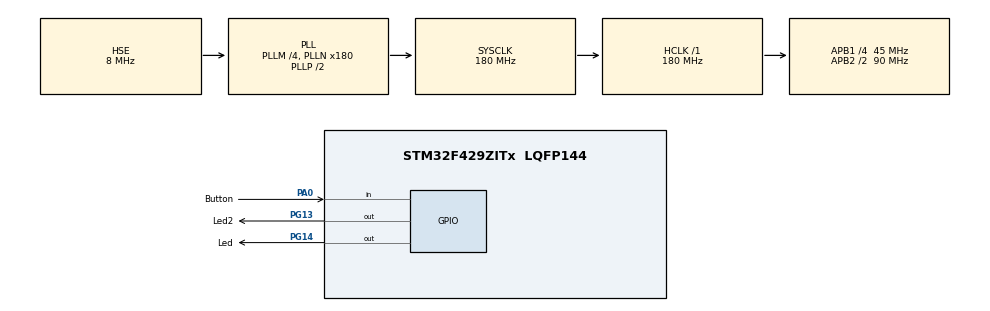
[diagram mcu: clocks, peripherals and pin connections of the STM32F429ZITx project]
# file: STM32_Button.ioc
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Mcu.Family=STM32F4
Mcu.Name=STM32F429ZITx
Mcu.Package=LQFP144
NVIC.PriorityGroup=NVIC_PRIORITYGROUP_4
PA0/WKUP.GPIO_Label=Button
PA0/WKUP.Signal=GPIO_Input
PA13.Mode=Serial_Wire
PA13.Signal=SYS_JTMS-SWDIO
PA14.Mode=Serial_Wire
PA14.Signal=SYS_JTCK-SWCLK
PG13.GPIO_Label=Led2
PG13.Signal=GPIO_Output
PG14.GPIO_Label=Led
PG14.Signal=GPIO_Output
PH0/OSC_IN.Mode=HSE-External-Oscillator
PH0/OSC_IN.Signal=RCC_OSC_IN
PH1/OSC_OUT.Mode=HSE-External-Oscillator
PH1/OSC_OUT.Signal=RCC_OSC_OUT
ProjectManager.HeapSize=0x200
ProjectManager.StackSize=0x400
ProjectManager.TargetToolchain=SW4STM32
RCC.48MHZClocksFreq_Value=90000000
RCC.AHBFreq_Value=180000000
RCC.APB1CLKDivider=RCC_HCLK_DIV4
RCC.APB1Freq_Value=45000000
RCC.APB1TimFreq_Value=90000000
RCC.APB2CLKDivider=RCC_HCLK_DIV2
RCC.APB2Freq_Value=90000000
RCC.APB2TimFreq_Value=180000000
RCC.CortexFreq_Value=180000000
RCC.HCLKFreq_Value=180000000
RCC.HSE_VALUE=8000000
RCC.HSI_VALUE=16000000
RCC.LSE_VALUE=32768
RCC.PLLM=4
RCC.PLLN=180
RCC.PLLSourceVirtual=RCC_PLLSOURCE_HSE
RCC.SYSCLKFreq_VALUE=180000000
RCC.SYSCLKSource=RCC_SYSCLKSOURCE_PLLCLK
RCC.VCOOutputFreq_Value=360000000
board=custom

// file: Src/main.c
/**
  ******************************************************************************
  * @file           : main.c
  * @brief          : Main program body
  ******************************************************************************
  ** This notice applies to any and all portions of this file
  * that are not between comment pairs USER CODE BEGIN and
  * USER CODE END. Other portions of this file, whether
  * inserted by the user or by software development tools
  * are owned by their respective copyright owners.
  *
  * COPYRIGHT(c) 2018 STMicroelectronics
  *
  * Redistribution and use in source and binary forms, with or without modification,
  * are permitted provided that the following conditions are met:
  *   1. Redistributions of source code must retain the above copyright notice,
  *      this list of conditions and the following disclaimer.
  *   2. Redistributions in binary form must reproduce the above copyright notice,
  *      this list of conditions and the following disclaimer in the documentation
  *      and/or other materials provided with the distribution.
  *   3. Neither the name of STMicroelectronics nor the names of its contributors
  *      may be used to endorse or promote products derived from this software
  *      without specific prior written permission.
  *
  * THIS SOFTWARE IS PROVIDED BY THE COPYRIGHT HOLDERS AND CONTRIBUTORS "AS IS"
  * AND ANY EXPRESS OR IMPLIED WARRANTIES, INCLUDING, BUT NOT LIMITED TO, THE
  * IMPLIED WARRANTIES OF MERCHANTABILITY AND FITNESS FOR A PARTICULAR PURPOSE ARE
  * DISCLAIMED. IN NO EVENT SHALL THE COPYRIGHT HOLDER OR CONTRIBUTORS BE LIABLE
  * FOR ANY DIRECT, INDIRECT, INCIDENTAL, SPECIAL, EXEMPLARY, OR CONSEQUENTIAL
  * DAMAGES (INCLUDING, BUT NOT LIMITED TO, PROCUREMENT OF SUBSTITUTE GOODS OR
  * SERVICES; LOSS OF USE, DATA, OR PROFITS; OR BUSINESS INTERRUPTION) HOWEVER
  * CAUSED AND ON ANY THEORY OF LIABILITY, WHETHER IN CONTRACT, STRICT LIABILITY,
  * OR TORT (INCLUDING NEGLIGENCE OR OTHERWISE) ARISING IN ANY WAY OUT OF THE USE
  * OF THIS SOFTWARE, EVEN IF ADVISED OF THE POSSIBILITY OF SUCH DAMAGE.
  *
  ******************************************************************************
  */
#include "main.h"
#include "stm32f4xx_hal.h"

/* USER CODE BEGIN PV */
/* Private variables ---------------------------------------------------------*/

/* USER CODE END PV */

void SystemClock_Config(void);
static void MX_GPIO_Init(void);

/* USER CODE BEGIN PFP */
/* Private function prototypes -----------------------------------------------*/

/* USER CODE END PFP */

/* USER CODE BEGIN 0 */
#define DEBOUNCING_PERIOD 5
#define BLINKING_TIMER 500

typedef enum ButtonState ButtonState;
enum ButtonState{
	BUTTON_RELEASED,
	BUTTON_PRESSED,
	BUTTON_RELEASED_DEBOUNCING,
	BUTTON_PRESSED_DEBOUNCING,
};

typedef struct Button Button;
struct Button{
	ButtonState buttonState;//to keep the state of the button
	int prevTick;
	ButtonState state;//state machine for function handleButton
};

typedef enum LedState LedState;
enum LedState{
	LED_OFF,
	LED_ON,
};

typedef struct LedButtonInfo LedButtonInfo;
struct LedButtonInfo
{
  LedState currentLedState;
  ButtonState previousButtonState;
};

typedef struct LedInfo LedInfo;//for led blink
struct LedInfo
{
	LedState ledState;
	uint32_t prevTick;
};

void varButtoninit(Button *button);
void varStateinit(LedButtonInfo *state);
ButtonState getButtonState(Button *button);
void turnLed(LedState ledState);
void handleButton(Button *button);
void doTapTurnOnTapTurnOffLed(LedButtonInfo *state,Button *Button);
void doBlinking(LedInfo *ledState);
void turnLed2(LedState ledState);

ButtonState getButtonState(Button *button)
{
	return button->buttonState;
}

void turnLed(LedState ledState)
{
	if(ledState == LED_OFF)
	{
		HAL_GPIO_WritePin(Led_GPIO_Port, Led_Pin, GPIO_PIN_RESET);
	}
	else if(ledState == LED_ON)
	{
		HAL_GPIO_WritePin(Led_GPIO_Port, Led_Pin, GPIO_PIN_SET);
	}
}

void turnLed2(LedState ledState)
{
	if(ledState == LED_OFF)
	{
		HAL_GPIO_WritePin(Led2_GPIO_Port, Led2_Pin, GPIO_PIN_RESET);
	}
	else if(ledState == LED_ON)
	{
		HAL_GPIO_WritePin(Led2_GPIO_Port, Led2_Pin, GPIO_PIN_SET);
	}
}

void handleButton(Button *button)
{
	switch(button->state){
		case BUTTON_RELEASED :
			button->buttonState = BUTTON_RELEASED;
			if(HAL_GPIO_ReadPin(Button_GPIO_Port, Button_Pin))
			{
				button->state = BUTTON_PRESSED_DEBOUNCING;
				button->prevTick = HAL_GetTick();
			}
			break;

		case BUTTON_PRESSED_DEBOUNCING :
			if(HAL_GetTick() >= button->prevTick+DEBOUNCING_PERIOD)
			{
				if(HAL_GPIO_ReadPin(Button_GPIO_Port, Button_Pin))
				{
					button->state = BUTTON_PRESSED;
					button->buttonState = BUTTON_PRESSED;
				}
				else
				{
					button->state = BUTTON_RELEASED;
					button->buttonState = BUTTON_RELEASED;
				}
			}
			break;

		case BUTTON_PRESSED :
			button->buttonState = BUTTON_PRESSED;
			if(!HAL_GPIO_ReadPin(Button_GPIO_Port, Button_Pin))
			{
				button->state = BUTTON_RELEASED_DEBOUNCING;
				button->prevTick = HAL_GetTick();
			}
			break;

		case BUTTON_RELEASED_DEBOUNCING :
			if(HAL_GetTick() >= button->prevTick+DEBOUNCING_PERIOD)
			{
				if(!HAL_GPIO_ReadPin(Button_GPIO_Port, Button_Pin))
				{
					button->state = BUTTON_RELEASED;
					button->buttonState = BUTTON_RELEASED;
				}
				else
				{
					button->state = BUTTON_PRESSED;
					button->buttonState = BUTTON_PRESSED;
				}
			}
			break;
	}
}

void doTapTurnOnTapTurnOffLed(LedButtonInfo *state,Button *Button)
{
  int button = state->previousButtonState;
  if(state->currentLedState == LED_OFF)
  {
    switch(button)
    {
      case BUTTON_RELEASED:
        if(getButtonState(Button) == BUTTON_RELEASED)
        {
          state->currentLedState = LED_OFF;
          state->previousButtonState = BUTTON_RELEASED;
        }
        else
        {
          turnLed(LED_ON);
          state->currentLedState = LED_OFF;
          state->previousButtonState = BUTTON_PRESSED;
        }
        break;

      case BUTTON_PRESSED:
        if(getButtonState(Button) == BUTTON_RELEASED)
        {
          state->currentLedState = LED_ON;
          state->previousButtonState = BUTTON_RELEASED;
        }
        else
        {
          state->currentLedState = LED_OFF;
          state->previousButtonState = BUTTON_PRESSED;
        }
        break;

    }
  }

  else if(state->currentLedState == LED_ON)
  {
    switch(button)
    {
      case BUTTON_RELEASED:
        if(getButtonState(Button) == BUTTON_RELEASED)
        {
          state->currentLedState = LED_ON;
          state->previousButtonState = BUTTON_RELEASED;
        }
        else
        {
          state->currentLedState = LED_ON;
          state->previousButtonState = BUTTON_PRESSED;
        }
        break;

      case BUTTON_PRESSED:
        if(getButtonState(Button) == BUTTON_RELEASED)
        {
          turnLed(LED_OFF);
          state->currentLedState = LED_OFF;
          state->previousButtonState = BUTTON_RELEASED;
        }
        else
        {
          state->currentLedState = LED_ON;
          state->previousButtonState = BUTTON_PRESSED;
        }
        break;

    }
  }
}

void varButtoninit(Button *button)
{
  button->state = HAL_GPIO_ReadPin(Button_GPIO_Port, Button_Pin);
  button->buttonState = HAL_GPIO_ReadPin(Button_GPIO_Port, Button_Pin);
  button->prevTick = 0;
}

void varStateinit(LedButtonInfo *state)
{
	state->currentLedState = LED_OFF;
	state->previousButtonState = HAL_GPIO_ReadPin(Button_GPIO_Port, Button_Pin);
}

void ledInfo_Init(LedInfo *ledInfo)
{
	ledInfo->ledState = LED_OFF;
	ledInfo->prevTick = HAL_GetTick();
}

void doBlinking(LedInfo *ledState)
{

	switch(ledState->ledState)
	{
		case LED_OFF :
			if(HAL_GetTick() > ledState->prevTick + BLINKING_TIMER)
			{
				ledState->prevTick = HAL_GetTick();
				ledState->ledState = LED_ON;
				turnLed2(LED_ON);
			}
			break;

		case LED_ON :
			if(HAL_GetTick() > ledState->prevTick + BLINKING_TIMER)
			{
				ledState->prevTick = HAL_GetTick();
				ledState->ledState = LED_OFF;
				turnLed2(LED_OFF);
			}
			break;
	}

}
/* USER CODE END 0 */

int main(void)
{
  /* USER CODE BEGIN 1 */
	  LedButtonInfo state;
	  Button buttonInfo;
	  LedInfo ledState;

	  varButtoninit(&buttonInfo);
	  varStateinit(&state);
	  ledInfo_Init(&ledState);
  /* USER CODE END 1 */

  /* MCU Configuration----------------------------------------------------------*/

  /* Reset of all peripherals, Initializes the Flash interface and the Systick. */
  HAL_Init();

  /* Configure the system clock */
  SystemClock_Config();

  /* Initialize all configured peripherals */
  MX_GPIO_Init();

  /* Infinite loop */
  /* USER CODE BEGIN WHILE */
  while (1)
  {
	  doTapTurnOnTapTurnOffLed(&state,&buttonInfo);
	  handleButton(&buttonInfo);
	  doBlinking(&ledState);
  /* USER CODE END WHILE */

  }

}

void SystemClock_Config(void)
{

  RCC_OscInitTypeDef RCC_OscInitStruct;
  RCC_ClkInitTypeDef RCC_ClkInitStruct;

    /**Configure the main internal regulator output voltage
    */
  __HAL_RCC_PWR_CLK_ENABLE();

  __HAL_PWR_VOLTAGESCALING_CONFIG(PWR_REGULATOR_VOLTAGE_SCALE1);

    /**Initializes the CPU, AHB and APB busses clocks
    */
  RCC_OscInitStruct.OscillatorType = RCC_OSCILLATORTYPE_HSE;
  RCC_OscInitStruct.HSEState = RCC_HSE_ON;
  RCC_OscInitStruct.PLL.PLLState = RCC_PLL_ON;
  RCC_OscInitStruct.PLL.PLLSource = RCC_PLLSOURCE_HSE;
  RCC_OscInitStruct.PLL.PLLM = 4;
  RCC_OscInitStruct.PLL.PLLN = 180;
  RCC_OscInitStruct.PLL.PLLP = RCC_PLLP_DIV2;
  RCC_OscInitStruct.PLL.PLLQ = 4;
  if (HAL_RCC_OscConfig(&RCC_OscInitStruct) != HAL_OK)
  {
    _Error_Handler(__FILE__, __LINE__);
  }

    /**Activate the Over-Drive mode
    */
  if (HAL_PWREx_EnableOverDrive() != HAL_OK)
  {
    _Error_Handler(__FILE__, __LINE__);
  }

    /**Initializes the CPU, AHB and APB busses clocks
    */
  RCC_ClkInitStruct.ClockType = RCC_CLOCKTYPE_HCLK|RCC_CLOCKTYPE_SYSCLK
                              |RCC_CLOCKTYPE_PCLK1|RCC_CLOCKTYPE_PCLK2;
  RCC_ClkInitStruct.SYSCLKSource = RCC_SYSCLKSOURCE_PLLCLK;
  RCC_ClkInitStruct.AHBCLKDivider = RCC_SYSCLK_DIV1;
  RCC_ClkInitStruct.APB1CLKDivider = RCC_HCLK_DIV4;
  RCC_ClkInitStruct.APB2CLKDivider = RCC_HCLK_DIV2;

  if (HAL_RCC_ClockConfig(&RCC_ClkInitStruct, FLASH_LATENCY_5) != HAL_OK)
  {
    _Error_Handler(__FILE__, __LINE__);
  }

    /**Configure the Systick interrupt time
    */
  HAL_SYSTICK_Config(HAL_RCC_GetHCLKFreq()/1000);

    /**Configure the Systick
    */
  HAL_SYSTICK_CLKSourceConfig(SYSTICK_CLKSOURCE_HCLK);

  /* SysTick_IRQn interrupt configuration */
  HAL_NVIC_SetPriority(SysTick_IRQn, 0, 0);
}

/** Configure pins as
        * Analog
        * Input
        * Output
        * EVENT_OUT
        * EXTI
*/
static void MX_GPIO_Init(void)
{

  GPIO_InitTypeDef GPIO_InitStruct;

  /* GPIO Ports Clock Enable */
  __HAL_RCC_GPIOH_CLK_ENABLE();
  __HAL_RCC_GPIOA_CLK_ENABLE();
  __HAL_RCC_GPIOG_CLK_ENABLE();

  /*Configure GPIO pin Output Level */
  HAL_GPIO_WritePin(GPIOG, Led2_Pin|Led_Pin, GPIO_PIN_RESET);

  /*Configure GPIO pin : Button_Pin */
  GPIO_InitStruct.Pin = Button_Pin;
  GPIO_InitStruct.Mode = GPIO_MODE_INPUT;
  GPIO_InitStruct.Pull = GPIO_NOPULL;
  HAL_GPIO_Init(Button_GPIO_Port, &GPIO_InitStruct);

  /*Configure GPIO pins : Led2_Pin Led_Pin */
  GPIO_InitStruct.Pin = Led2_Pin|Led_Pin;
  GPIO_InitStruct.Mode = GPIO_MODE_OUTPUT_PP;
  GPIO_InitStruct.Pull = GPIO_NOPULL;
  GPIO_InitStruct.Speed = GPIO_SPEED_FREQ_LOW;
  HAL_GPIO_Init(GPIOG, &GPIO_InitStruct);

}

void _Error_Handler(char *file, int line)
{
  while(1)
  {
  }
}

/************************ (C) COPYRIGHT STMicroelectronics *****END OF FILE****/
